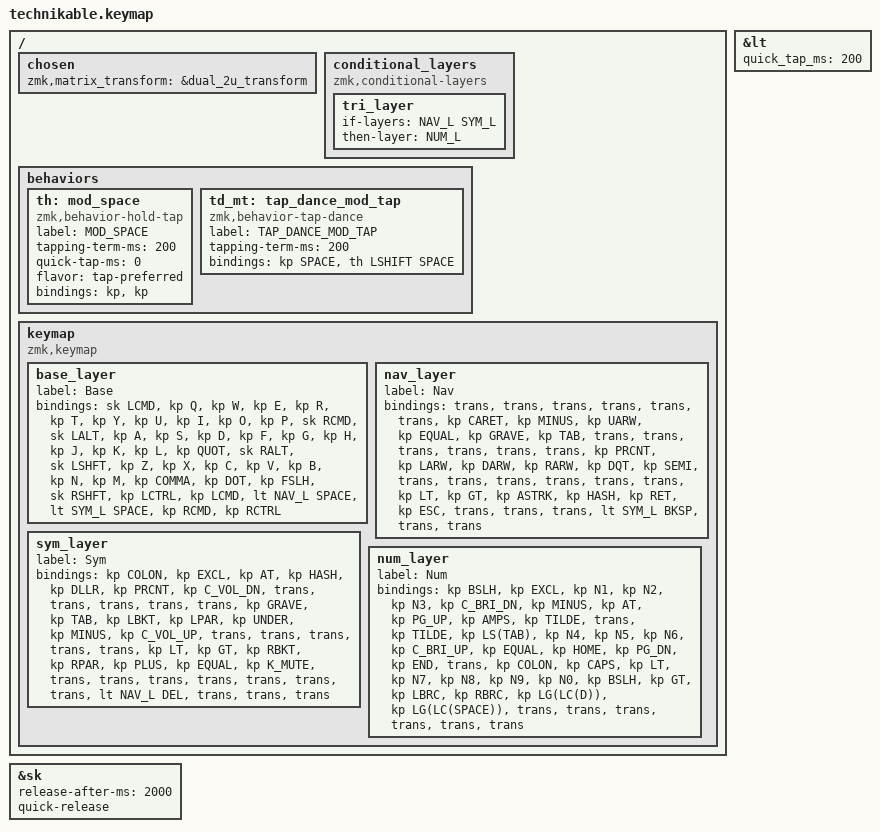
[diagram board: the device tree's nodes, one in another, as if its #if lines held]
/*
 * Copyright (c) 2022 Pete Johanson
 *
 * SPDX-License-Identifier: MIT
 */

#include <behaviors.dtsi>
#include <dt-bindings/zmk/keys.h>
#include <dt-bindings/zmk/bt.h>
#include <dt-bindings/zmk/outputs.h>

// #define TBLE_ORTHO   true
#define TBLE_MIT     true
// #define TBLE_DUAL_2U true

#define BAS_L 0
#define NAV_L 1
#define SYM_L 2
#define NUM_L 3

// Using layer taps on thumbs, having quick tap as well helps w/ repeating space/backspace
&lt { quick_tap_ms = <200>; };

&sk {
    release-after-ms = <2000>;
    quick-release;
};

#define BT(n) BT_SEL n

/ {
    chosen {
       zmk,matrix_transform =
#ifdef TBLE_DUAL_2U
                       &dual_2u_transform;
#elif defined(TBLE_MIT)
                       &mit_transform;
#else
                       &ortho_transform;
#endif
    };

    conditional_layers {
        compatible = "zmk,conditional-layers";
	tri_layer {
	    if-layers = <NAV_L SYM_L>;
	    then-layer = <NUM_L>;
	};
    };
    
    // tap-hold
    behaviors {
        th: mod_space {
            compatible = "zmk,behavior-hold-tap";
            label = "MOD_SPACE";
            #binding-cells = <2>;
            tapping-term-ms = <200>;
            quick-tap-ms = <0>;
            flavor = "tap-preferred";
            bindings = <&kp>, <&kp>;
        };
    };
    
    // SPACE on tap, mod-tap space/shift on double-tap
    behaviors {
        td_mt: tap_dance_mod_tap {
            compatible = "zmk,behavior-tap-dance";
            label = "TAP_DANCE_MOD_TAP";
            #binding-cells = <0>;
            tapping-term-ms = <200>;
            bindings = <&kp SPACE>, <&th LSHIFT SPACE>;
        };
    };

    keymap {
        compatible = "zmk,keymap";

        base_layer {
            label = "Base";
            bindings = <
 &sk LCMD   &kp Q      &kp W      &kp E       &kp R          &kp T          &kp Y            &kp U           &kp I       &kp O      &kp P         &sk RCMD 
 &sk LALT   &kp A      &kp S      &kp D       &kp F          &kp G          &kp H            &kp J           &kp K       &kp L      &kp QUOT      &sk RALT 
 &sk LSHFT  &kp Z      &kp X      &kp C       &kp V          &kp B          &kp N            &kp M           &kp COMMA   &kp DOT    &kp FSLH      &sk RSHFT
#ifdef TBLE_DUAL_2U
                       &kp LCTRL  &kp LCMD      &lt NAV_L SPACE                &lt SYM_L SPACE               &kp RCMD    &kp RCTRL
#elif defined(TBLE_MIT)
                       &kp LCTRL  &kp LCMD    &lt NAV_L BKSP        &th LSHIFT SPACE         &lt SYM_L SPACE &kp RCMD    &kp RCTRL
#else
                       &kp LCTRL  &kp LCMD    &lt NAV_L BKSP &th LSHIFT SPACE &kp SPACE      &mo SYM_L       &kp RCMD    &kp RCTRL
#endif
            >;
        };

        nav_layer {
            label = "Nav";
            bindings = <
&trans     &trans     &trans     &trans      &trans          &trans       &kp CARET  &kp MINUS      &kp UARW    &kp EQUAL  &kp GRAVE  &kp TAB
&trans     &trans     &trans     &trans      &trans          &trans       &kp PRCNT  &kp LARW       &kp DARW    &kp RARW   &kp DQT    &kp SEMI
&trans     &trans     &trans     &trans      &trans          &trans       &kp LT     &kp GT         &kp ASTRK   &kp HASH   &kp RET    &kp ESC
#ifdef TBLE_DUAL_2U
                      &trans     &trans              &trans                     &lt SYM_L BKSP      &trans      &trans
#elif defined(TBLE_MIT)
                      &bt BT(0)  &bt BT(1)   &trans              &mt LSHIFT BKSP     &lt SYM_L DEL  &bt BT(2)   &bt BT_CLR
#else
                      &trans     &trans      &trans          &trans       &mt LSHIFT BKSP &lt SYM_L DEL &trans      &trans
#endif
            >;
        };

        sym_layer {
            label = "Sym";
            bindings = <
&kp COLON  &kp EXCL   &kp AT     &kp HASH    &kp DLLR   &kp PRCNT   &kp C_VOL_DN  &trans         &trans       &trans       &trans     &trans
&kp GRAVE  &kp TAB    &kp LBKT   &kp LPAR    &kp UNDER  &kp MINUS   &kp C_VOL_UP  &trans         &trans       &trans       &trans     &trans
&kp LT     &kp GT     &kp RBKT   &kp RPAR    &kp PLUS   &kp EQUAL   &kp K_MUTE    &trans         &trans       &trans       &trans     &trans
#ifdef TBLE_DUAL_2U
                      &trans     &trans          &lt NAV_L DEL             &trans               &trans       &trans
#elif defined(TBLE_MIT)
                      &trans     &trans      &lt NAV_L BKSP  &mt LSHIFT DEL      &trans         &trans       &trans
#else
                      &trans     &trans      &trans    &th LSHIFT DEL &trans     &trans         &trans       &trans
#endif
            >;
        };

        num_layer {
            label = "Num";
            bindings = <
&kp BSLH  &kp EXCL    &kp N1     &kp N2      &kp N3    &kp C_BRI_DN  &kp MINUS   &kp AT     &kp PG_UP   &kp AMPS     &kp TILDE &trans
&kp TILDE &kp LS(TAB) &kp N4     &kp N5      &kp N6    &kp C_BRI_UP  &kp EQUAL   &kp HOME   &kp PG_DN   &kp END      &trans    &kp COLON
&kp CAPS  &kp LT      &kp N7     &kp N8      &kp N9    &kp N0        &kp BSLH    &kp GT     &kp LBRC    &kp RBRC     &kp LG(LC(D)) &kp LG(LC(SPACE))
#ifdef TBLE_DUAL_2U
                      &trans     &trans               &trans                &trans           &trans       &trans
#elif defined(TBLE_MIT)
                      &trans     &trans      &trans             &trans            &trans     &trans       &trans
#else
                      &trans     &trans      &trans    &trans       &trans        &trans     &trans       &trans
#endif
            >;
        };

    };
};
